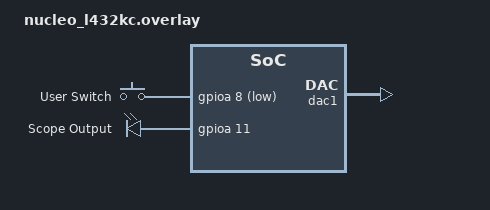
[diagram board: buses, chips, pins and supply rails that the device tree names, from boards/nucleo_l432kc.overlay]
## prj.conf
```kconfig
CONFIG_GPIO=y
CONFIG_DAC=y
```

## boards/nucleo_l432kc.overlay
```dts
/ {
	aliases {

		sw-input = &button_d9; /* this is my input because i called it that*/

		wave-out = &pin_d10; /* same sh*t */
	};

	gpio_keys {
		compatible = "gpio-keys";

		button_d9: button_d9 {
			gpios = <&gpioa 8 (GPIO_PULL_UP | GPIO_ACTIVE_LOW)>;
			label = "User Switch";
		};
	};

	/* def outs */
	leds {
		compatible = "gpio-leds";
		
		pin_d10: scope_out {
			gpios = <&gpioa 11 GPIO_ACTIVE_HIGH>;
			label = "Scope Output";
		};
	};
	
};
//outside the / node i think ????
&dac1 {
 status = "okay"; // This “okay” enables the &dac1 node device.
};
```

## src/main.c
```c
/*
Program 6: sawtooth wave generator using DAC
Description: 
Course: 1064
Author: Daniel Mui
Date: 2/2/2026
 */

 //import tarrifs
#include <zephyr/kernel.h>
#include <zephyr/drivers/dac.h>

//init
static const struct device *const dac_dev = DEVICE_DT_GET(DT_NODELABEL(dac1));
static const struct dac_channel_cfg dac_ch_cfg = {
    .channel_id = 1,
    .resolution = 12
};

int main(void){
    dac_channel_setup(dac_dev, &dac_ch_cfg);
    //def vars for shape of wave
    int max_val = 3723; // Approx 3.0V for 12-bit DAC with 3.3V reference
    int step_size = 100; // Step size for ramping up
    int sleep_time_us = 270; // Sleep time

    while (1) {
        // Generate the ramp up
        for (int i = 0; i < max_val; i += step_size) {
            dac_write_value(dac_dev, 1, i);
            k_busy_wait(sleep_time_us); 
        }
        // Reset to 0V fro drop in sawtooh
        dac_write_value(dac_dev, 1, 0);
    }
    return 0; /*we write good code here fr fr*/
}
```
